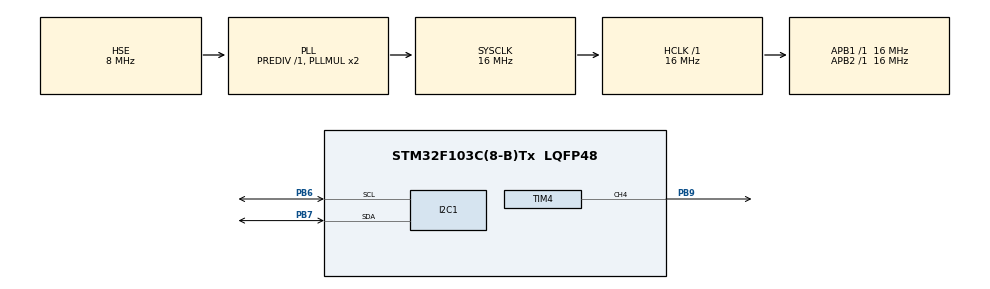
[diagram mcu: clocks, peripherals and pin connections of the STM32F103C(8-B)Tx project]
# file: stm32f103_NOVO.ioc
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Mcu.Family=STM32F1
Mcu.Name=STM32F103C(8-B)Tx
Mcu.Package=LQFP48
NVIC.PriorityGroup=NVIC_PRIORITYGROUP_4
PB6.Mode=I2C
PB6.Signal=I2C1_SCL
PB7.Mode=I2C
PB7.Signal=I2C1_SDA
PB9.Signal=S_TIM4_CH4
PD0-OSC_IN.Mode=HSE-External-Oscillator
PD0-OSC_IN.Signal=RCC_OSC_IN
PD1-OSC_OUT.Mode=HSE-External-Oscillator
PD1-OSC_OUT.Signal=RCC_OSC_OUT
ProjectManager.HeapSize=0x200
ProjectManager.StackSize=0x400
ProjectManager.TargetToolchain=STM32CubeIDE
RCC.AHBFreq_Value=16000000
RCC.APB1Freq_Value=16000000
RCC.APB1TimFreq_Value=16000000
RCC.APB2Freq_Value=16000000
RCC.APB2TimFreq_Value=16000000
RCC.HCLKFreq_Value=16000000
RCC.PLLSourceVirtual=RCC_PLLSOURCE_HSE
RCC.SYSCLKFreq_VALUE=16000000
RCC.SYSCLKSource=RCC_SYSCLKSOURCE_PLLCLK
RCC.USBFreq_Value=16000000
SH.S_TIM4_CH4.0=TIM4_CH4,PWM Generation4 CH4
TIM4.Channel-PWM\ Generation4\ CH4=TIM_CHANNEL_4
TIM4.Period=625
TIM4.Prescaler=127
VP_SYS_VS_ND.Mode=No_Debug
board=custom

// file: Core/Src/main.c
/* USER CODE BEGIN Header */
/**
  ******************************************************************************
  * @file           : main.c
  * @brief          : Main program body
  ******************************************************************************
  * @attention
  *
  * Copyright (c) 2023 STMicroelectronics.
  * All rights reserved.
  *
  * This software is licensed under terms that can be found in the LICENSE file
  * in the root directory of this software component.
  * If no LICENSE file comes with this software, it is provided AS-IS.
  *
  ******************************************************************************
  */
/* USER CODE END Header */
#include "main.h"

/* USER CODE BEGIN Includes */
#include "LEDDriverAPI.h"
/* USER CODE END Includes */

 I2C_HandleTypeDef hi2c1;

TIM_HandleTypeDef htim4;

void SystemClock_Config(void);
static void MX_GPIO_Init(void);
static void MX_I2C1_Init(void);
static void MX_TIM4_Init(void);

int main(void)
{

  /* MCU Configuration--------------------------------------------------------*/

  /* Reset of all peripherals, Initializes the Flash interface and the Systick. */
  HAL_Init();

  /* Configure the system clock */
  SystemClock_Config();

  /* Initialize all configured peripherals */
  MX_GPIO_Init();
  MX_I2C1_Init();
  MX_TIM4_Init();
  /* USER CODE BEGIN 2 */
  HAL_TIM_PWM_Start(&htim4, TIM_CHANNEL_4);

  LEDDriverInit(I2C);
  LEDDriverSetValue(50);

  LEDDriverInit(PWM);
  LEDDriverSetValue(0);

  /* USER CODE END 2 */

  /* Infinite loop */
  /* USER CODE BEGIN WHILE */
  while (1)
  {
	  LEDDriverSetValue(50);
	  HAL_Delay(100);
	  LEDDriverSetValue(100);
	  HAL_Delay(100);
	  LEDDriverSetValue(0);
	  HAL_Delay(100);
    /* USER CODE END WHILE */
  }
  /* USER CODE END 3 */
}

void SystemClock_Config(void)
{
  RCC_OscInitTypeDef RCC_OscInitStruct = {0};
  RCC_ClkInitTypeDef RCC_ClkInitStruct = {0};

  /** Initializes the RCC Oscillators according to the specified parameters
  * in the RCC_OscInitTypeDef structure.
  */
  RCC_OscInitStruct.OscillatorType = RCC_OSCILLATORTYPE_HSE;
  RCC_OscInitStruct.HSEState = RCC_HSE_ON;
  RCC_OscInitStruct.HSEPredivValue = RCC_HSE_PREDIV_DIV1;
  RCC_OscInitStruct.HSIState = RCC_HSI_ON;
  RCC_OscInitStruct.PLL.PLLState = RCC_PLL_ON;
  RCC_OscInitStruct.PLL.PLLSource = RCC_PLLSOURCE_HSE;
  RCC_OscInitStruct.PLL.PLLMUL = RCC_PLL_MUL2;
  if (HAL_RCC_OscConfig(&RCC_OscInitStruct) != HAL_OK)
  {
    Error_Handler();
  }

  /** Initializes the CPU, AHB and APB buses clocks
  */
  RCC_ClkInitStruct.ClockType = RCC_CLOCKTYPE_HCLK|RCC_CLOCKTYPE_SYSCLK
                              |RCC_CLOCKTYPE_PCLK1|RCC_CLOCKTYPE_PCLK2;
  RCC_ClkInitStruct.SYSCLKSource = RCC_SYSCLKSOURCE_PLLCLK;
  RCC_ClkInitStruct.AHBCLKDivider = RCC_SYSCLK_DIV1;
  RCC_ClkInitStruct.APB1CLKDivider = RCC_HCLK_DIV1;
  RCC_ClkInitStruct.APB2CLKDivider = RCC_HCLK_DIV1;

  if (HAL_RCC_ClockConfig(&RCC_ClkInitStruct, FLASH_LATENCY_0) != HAL_OK)
  {
    Error_Handler();
  }
}

static void MX_I2C1_Init(void)
{

  hi2c1.Instance = I2C1;
  hi2c1.Init.ClockSpeed = 100000;
  hi2c1.Init.DutyCycle = I2C_DUTYCYCLE_2;
  hi2c1.Init.OwnAddress1 = 0;
  hi2c1.Init.AddressingMode = I2C_ADDRESSINGMODE_7BIT;
  hi2c1.Init.DualAddressMode = I2C_DUALADDRESS_DISABLE;
  hi2c1.Init.OwnAddress2 = 0;
  hi2c1.Init.GeneralCallMode = I2C_GENERALCALL_DISABLE;
  hi2c1.Init.NoStretchMode = I2C_NOSTRETCH_DISABLE;
  if (HAL_I2C_Init(&hi2c1) != HAL_OK)
  {
    Error_Handler();
  }

}

static void MX_TIM4_Init(void)
{

  TIM_MasterConfigTypeDef sMasterConfig = {0};
  TIM_OC_InitTypeDef sConfigOC = {0};

  htim4.Instance = TIM4;
  htim4.Init.Prescaler = 127;
  htim4.Init.CounterMode = TIM_COUNTERMODE_UP;
  htim4.Init.Period = 625;
  htim4.Init.ClockDivision = TIM_CLOCKDIVISION_DIV1;
  htim4.Init.AutoReloadPreload = TIM_AUTORELOAD_PRELOAD_DISABLE;
  if (HAL_TIM_PWM_Init(&htim4) != HAL_OK)
  {
    Error_Handler();
  }
  sMasterConfig.MasterOutputTrigger = TIM_TRGO_RESET;
  sMasterConfig.MasterSlaveMode = TIM_MASTERSLAVEMODE_DISABLE;
  if (HAL_TIMEx_MasterConfigSynchronization(&htim4, &sMasterConfig) != HAL_OK)
  {
    Error_Handler();
  }
  sConfigOC.OCMode = TIM_OCMODE_PWM1;
  sConfigOC.Pulse = 0;
  sConfigOC.OCPolarity = TIM_OCPOLARITY_HIGH;
  sConfigOC.OCFastMode = TIM_OCFAST_DISABLE;
  if (HAL_TIM_PWM_ConfigChannel(&htim4, &sConfigOC, TIM_CHANNEL_4) != HAL_OK)
  {
    Error_Handler();
  }
  HAL_TIM_MspPostInit(&htim4);

}

static void MX_GPIO_Init(void)
{

  /* GPIO Ports Clock Enable */
  __HAL_RCC_GPIOD_CLK_ENABLE();
  __HAL_RCC_GPIOB_CLK_ENABLE();

}

void Error_Handler(void)
{
  __disable_irq();
  while (1)
  {
  }
}
